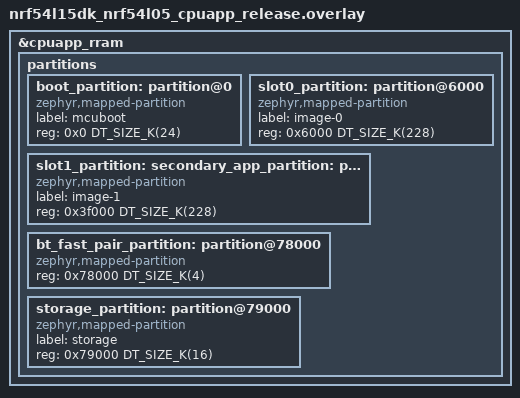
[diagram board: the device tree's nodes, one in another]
/*
 * Copyright (c) 2026 Nordic Semiconductor ASA
 *
 * SPDX-License-Identifier: LicenseRef-Nordic-5-Clause
 */

&cpuapp_rram {
	/* Redefine the "partitions" DTS node. */
	/delete-node/ partitions;

	partitions {
		ranges;
		#address-cells = <1>;
		#size-cells = <1>;

		boot_partition: partition@0 {
			compatible = "zephyr,mapped-partition";
			label = "mcuboot";
			reg = <0x0 DT_SIZE_K(24)>;
		};

		slot0_partition: partition@6000 {
			compatible = "zephyr,mapped-partition";
			label = "image-0";
			reg = <0x6000 DT_SIZE_K(228)>;
		};

		slot1_partition: partition@3f000 {
			compatible = "zephyr,mapped-partition";
			label = "image-1";
			reg = <0x3f000 DT_SIZE_K(228)>;
		};

		bt_fast_pair_partition: partition@78000 {
			compatible = "zephyr,mapped-partition";
			reg = <0x78000 DT_SIZE_K(4)>;
		};

		storage_partition: partition@79000 {
			compatible = "zephyr,mapped-partition";
			label = "storage";
			reg = <0x79000 DT_SIZE_K(16)>;
		};
	};
};

secondary_app_partition: &slot1_partition {};
